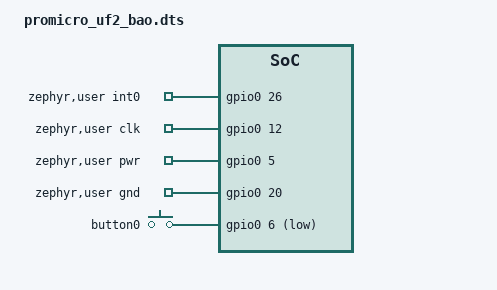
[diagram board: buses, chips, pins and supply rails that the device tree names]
// Copyright (c) 2024 Nordic Semiconductor ASA
// SPDX-License-Identifier: Apache-2.0

/dts-v1/;
#include "promicro_uf2.dts"

&pinctrl {
	spi3_default {
		group1 {
			psels = <NRF_PSEL(SPIM_MISO, 1, 9)>,
					<NRF_PSEL(SPIM_MOSI, 1, 8)>,
					<NRF_PSEL(SPIM_SCK, 0, 7)>;
		};
	};

	spi3_sleep {
		group1 {
			psels = <NRF_PSEL(SPIM_MISO, 1, 9)>,
					<NRF_PSEL(SPIM_MOSI, 1, 8)>,
					<NRF_PSEL(SPIM_SCK, 0, 7)>;
		};
	};
};

&button0 {
	gpios = <&gpio0 6 (GPIO_PULL_UP | GPIO_ACTIVE_LOW)>;
};

/ {
	aliases {
		sw0 = &button0;
	};

	zephyr,user {
		/delete-property/ int0-gpios;
		int0-gpios = <&gpio0 26 0>;
		clk-gpios = <&gpio0 12 GPIO_OPEN_DRAIN>;
		pwr-gpios = <&gpio0 5 GPIO_OPEN_SOURCE>;
		gnd-gpios = <&gpio0 20 GPIO_OPEN_DRAIN>;
	};
};

/delete-node/ &i2c0;

&spi3 {
	cs-gpios = <&gpio0 4 GPIO_ACTIVE_LOW>;
};
